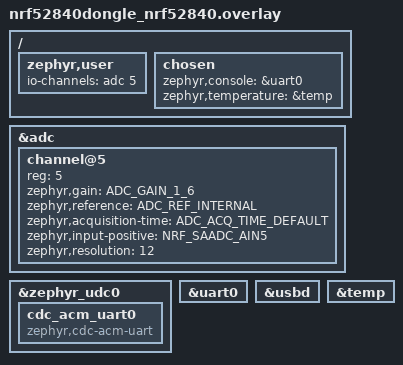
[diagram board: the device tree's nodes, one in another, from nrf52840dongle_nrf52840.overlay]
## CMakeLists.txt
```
# SPDX-License-Identifier: Apache-2.0

cmake_minimum_required(VERSION 3.20.0)
find_package(Zephyr REQUIRED HINTS $ENV{ZEPHYR_BASE})
project(central)

target_sources(app PRIVATE
  src/main.c
  src/util.c
  src/cmd_handler.c
  src/md_cmd.c
  src/shell.c
)

zephyr_library_include_directories(${ZEPHYR_BASE}/samples/bluetooth)
```

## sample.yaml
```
sample:
  name: Bluetooth Central
tests:
  sample.bluetooth.central:
    harness: bluetooth
    platform_allow: qemu_cortex_m3 qemu_x86
    tags: bluetooth
    integration_platforms:
      - qemu_cortex_m3
```

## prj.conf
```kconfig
CONFIG_BT=y
CONFIG_BT_CENTRAL=y
CONFIG_BT_EXT_ADV=y
CONFIG_BT_PER_ADV_SYNC=y
CONFIG_BT_DEBUG_LOG=y
CONFIG_BT_DEVICE_NAME="Central Periodic Advertising Receiver"
CONFIG_BT_PER_ADV_SYNC_TRANSFER_SENDER=y
CONFIG_BT_GATT_CLIENT=y

# enable uart driver
CONFIG_SERIAL=y
CONFIG_UART_INTERRUPT_DRIVEN=y
CONFIG_UART_LINE_CTRL=y

# enable console
CONFIG_CONSOLE=y
CONFIG_UART_CONSOLE=y
CONFIG_STDOUT_CONSOLE=y

CONFIG_USB_DEVICE_INITIALIZE_AT_BOOT=n
CONFIG_USB_DEVICE_STACK=y
CONFIG_USB_DEVICE_PRODUCT="BLE Throttle Central"

CONFIG_BT_DIS=y
CONFIG_BT_DIS_SERIAL_NUMBER=y
CONFIG_BT_DIS_MODEL="nRF52840_Acserver"
CONFIG_BT_DIS_MANUF="Br1Ge9se"
CONFIG_BT_DIS_SERIAL_NUMBER_STR="001001"

CONFIG_GETOPT=y
CONFIG_GETOPT_LONG=y

CONFIG_DK_LIBRARY=y
CONFIG_SENSOR=y
CONFIG_CBPRINTF_FP_SUPPORT=y

# Temperature sensor
CONFIG_TEMP_NRF5=y

# enable console for nRF52840 DK 
#CONFIG_CONSOLE_SUBSYS=y
#CONFIG_CONSOLE_GETCHAR=y
#CONFIG_CONSOLE_GETCHAR_BUFSIZE=64
#CONFIG_CONSOLE_PUTCHAR_BUFSIZE=512
```

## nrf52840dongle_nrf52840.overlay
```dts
/*
 * Copyright (c) 2021 Nordic Semiconductor ASA
 *
 * SPDX-License-Identifier: Apache-2.0
 */

 &adc {
	#address-cells = <1>;
	#size-cells = <0>;

	channel@5 {
		reg = <5>;
		zephyr,gain = "ADC_GAIN_1_6";
		zephyr,reference = "ADC_REF_INTERNAL";
		zephyr,acquisition-time = <ADC_ACQ_TIME_DEFAULT>;
		zephyr,input-positive = <NRF_SAADC_AIN5>; /* P0.03 */
		zephyr,resolution = <12>;
	};

};

&zephyr_udc0 {
	cdc_acm_uart0 {
		compatible = "zephyr,cdc-acm-uart";
	};
};

&uart0 {
    status = "okay";
};

&usbd {
    status = "okay";
};

/ {
    zephyr,user {
		io-channels = <&adc 5>;
	};
    
	chosen {
		/* zephyr,console = &usbd; */
		zephyr,console = &uart0;
		zephyr,temperature = &temp;
	};
};

&temp {
	status = "okay";
};
```

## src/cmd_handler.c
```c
/**
 * @file
 * @brief Shell Commands Handler
 *
 */

#include <string.h>
#include <stdio.h>
#include "util.h"

#define MAX_CMD 6

#define COMMAND_SUCCESS		0
#define COMMAND_ERROR		1
#define COMMAND_ERROR_USAGE	2

/*
 * Monitor Command Table
 */
typedef struct command {
	const char	*name;		/* Command Name			*/
	int		(*cmd)(int, char *[]); /* Implementation function	*/
	const char	*desc;		/* Short command description, start with lowercase */
	const char	*help;
}command;

extern int mem_md(int argc, char *argv[]);
extern int ble_info(void);
extern int print_rx_value(void);
extern int print_temp_value(void);

int helpCmd(int argc, char *argv[]);
int versCmd(int argc, char *argv[]);

struct command cmdTable[MAX_CMD] = {
		{"version", versCmd, "print out version info", NULL},
		{"info", ble_info, "print out BLE info", NULL},
		{"help", helpCmd, "print out command list", NULL},
		{"val", print_rx_value, "print out BLE Rx Value from client", NULL},
		{"temp", print_temp_value, "print out chip temperature", NULL},
		{"md", mem_md, "display (hex dump) a memory region",
		"Memory regions can be specified in two different forms: START+SIZE or START-END, if SIZE is omitted it defaults to 0x100"}
};


#define VERSION "  Shell V0.1 (beta) - "

int versCmd(int argc, char *argv[])
{
	char s1[60]=VERSION, s2[]=__DATE__, s3[]=__TIME__;
	strcat(s1, s2);
	strcat(s1, " * ");
	strcat(s1, s3);
	nc_printf ("\n%s\n\n", s1);
	return (COMMAND_SUCCESS);
}

char * help_string = "  ****** Commands help ******";

int helpCmd(int argc, char *argv[])
{
	int i;
	nc_printf ("\n\r%s\n\r", help_string);
	for (i=0; i<MAX_CMD; i++)
	{
		nc_printf("%s - %s\n\r", cmdTable[i].name, cmdTable[i].desc);
	}
	console_putc('\n');
	return (COMMAND_SUCCESS);
}


void cmd_usage(struct command *cmdtp)
{
	if (cmdtp->desc)
		nc_printf("\n%s - %s\n\n", cmdtp->name, cmdtp->desc);
	if (cmdtp->help)
		nc_printf("\nUsage: %s %s\n\n", cmdtp->name, cmdtp->help);
}

/*
 * find command table entry for a command
 */
struct command *find_cmd (const char *cmd)
{
	struct command *cmdtp;
	int i;

	for (i=0; i<MAX_CMD; i++) {
		cmdtp = &cmdTable[i];
		if (!strcmp(cmd, cmdtp->name))
			return cmdtp;
	}
	return NULL;	/* not found or ambiguous command */
}

int execute_command(int argc, char **argv)
{
	struct command *cmdtp;
	int ret;

	/* Look up command in command table */
	if ((cmdtp = find_cmd(argv[0]))) {
		/* OK - call function to do the command */
		ret = cmdtp->cmd(argc, argv);
		if (ret == COMMAND_ERROR_USAGE) {
			cmd_usage(cmdtp);
			ret = COMMAND_ERROR;
		}
	} else {
		nc_printf ("Unknown command '%s'\n", argv[0]);
		ret = COMMAND_ERROR;	/* give up after bad command */
	}
	return ret;
}
```

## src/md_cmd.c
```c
/**
 * Memory Functions
 *
 * Copied from FADS ROM, Dan Malek (dmalek@jlc.net)
 */



#include "util.h"

#define MSG_EMERG      0    /* system is unusable */
#define O_RWSIZE_SHIFT	18
#define O_RWSIZE_1	001000000
#define O_RWSIZE_2	002000000
#define O_RWSIZE_4	004000000
#define O_RWSIZE_8	010000000

#define PROT_READ	1

#define RW_BUF_SIZE	(unsigned)4096

#define COMMAND_SUCCESS		0
#define COMMAND_ERROR		1
#define COMMAND_ERROR_USAGE	2

#ifdef VERBOSE_DEBUG
#define LOGLEVEL	3
#elif defined DEBUG
#define LOGLEVEL	2
#else
#define LOGLEVEL	1
#endif

#define MAP_FAILED ((void *)-1)

#define DISP_LINE_LEN	16

typedef long long loff_t;
struct va_format {
	const char *fmt;
	va_list *va;
};

extern int optind;

volatile int arm_ignore_data_abort;
volatile int arm_data_abort_occurred;


/**
 * swab64 - return a byteswapped 64-bit value
 * @x: value to byteswap
 */
unsigned long long int swab64 (unsigned long long int x) {
    unsigned long long int ret = 0;
    unsigned char c;
    unsigned char * p = (unsigned char *) &x;
	int i;
    
    for (i=0; i<7; i++) {
        c = p[i];
        ret += c;
        ret = ret << 8;
    }
	c = p[i];
    ret += c;
    return ret;
}

/**
 * swab32 - return a byteswapped 32-bit value
 * @x: value to byteswap
 */
unsigned int swab32 (unsigned int x) {
    unsigned int i, ret = 0;
    unsigned char c;
    unsigned char * p = (unsigned char *) &x;
    
    for (i=0; i<3; i++) {
        c = p[i];
        ret += c;
        ret = ret << 8;
    }
	c = p[i];
    ret += c;
    return ret;
}

/**
 * swab16 - return a byteswapped 16-bit value
 * @x: value to byteswap
 */
unsigned short int swab16 (unsigned short int x) {
    unsigned short int ret = 0;
    unsigned char * p = (unsigned char *) &x;
    
	ret += p[0];
	ret = ret << 8;
	ret += p[1];

    return ret;
}


void data_abort_mask(void)
{
	arm_data_abort_occurred = 0;
	arm_ignore_data_abort = 1;
}

int data_abort_unmask(void)
{
	arm_ignore_data_abort = 0;

	return arm_data_abort_occurred != 0;
}

int memory_display(const void *addr, loff_t offs, unsigned nbytes, int size,
		   int swab);
int __pr_memory_display(int level, const void *addr, loff_t offs, unsigned nbytes,
			int size, int swab, const char *format, ...);

#define pr_fmt(fmt) fmt
#define pr_memory_display(level, addr, offs, nbytes, size, swab) \
	({	\
		(level) <= LOGLEVEL ? __pr_memory_display((level), (addr), \
				(offs), (nbytes), (size), (swab), pr_fmt("")) : 0; \
	 })

int __pr_memory_display(int level, const void *addr, loff_t offs, unsigned nbytes,
			int size, int swab, const char *fmt, ...)
{	        
	unsigned long linebytes, i;
	unsigned char *cp;
	unsigned char line[sizeof("00000000: 0000 0000 0000 0000  0000 0000 0000 0000            ................")];
	struct va_format vaf;
	int ret;
	va_list args;

	va_start(args, fmt);

	vaf.fmt = fmt;
	vaf.va = &args;

	/* Print the lines.
	 *
	 * We buffer all read data, so we can make sure data is read only
	 * once, and all accesses are with the specified bus width.
	 */
	do {
		unsigned char linebuf[DISP_LINE_LEN];
		uint64_t *ullp = (uint64_t *)linebuf;
		uint32_t *uip = (uint32_t *)linebuf;
		uint16_t *usp = (uint16_t *)linebuf;
		uint8_t *ucp = (uint8_t *)linebuf;
		unsigned char *pos = line;

		pos += sprintf(pos, "%08llx:", offs);
		linebytes = (nbytes > DISP_LINE_LEN) ? DISP_LINE_LEN : nbytes;

		for (i = 0; i < linebytes; i += size) {
			if (size == 8) {
				uint64_t res;
				data_abort_mask();
				res = *((uint64_t *)addr);
				if (swab)
					res = swab64(res);
				if (data_abort_unmask()) {
					res = 0xffffffffffffffffULL;
					pos += sprintf(pos, " xxxxxxxxxxxxxxxx");
				} else {
					pos += sprintf(pos, " %016llx", res);
				}
				*ullp++ = res;
			} else if (size == 4) {
				uint32_t res;
				data_abort_mask();
				res = *((uint32_t *)addr);
				if (swab)
					res = swab32(res);
				if (data_abort_unmask()) {
					res = 0xffffffff;
					pos += sprintf(pos, " xxxxxxxx");
				} else {
					pos += sprintf(pos, " %08x", res);
				}
				*uip++ = res;
			} else if (size == 2) {
				uint16_t res;
				data_abort_mask();
				res = *((uint16_t *)addr);
				if (swab)
					res = swab16(res);
				if (i > 1 && i % 8 == 0)
					pos += sprintf(pos, " ");
				if (data_abort_unmask()) {
					res = 0xffff;
					pos += sprintf(pos, " xxxx");
				} else {
					pos += sprintf(pos, " %04x", res);
				}
				*usp++ = res;
			} else {
				uint8_t res;
				data_abort_mask();
				res = *((uint8_t *)addr);
				if (i > 1 && i % 8 == 0)
					pos += sprintf(pos, " ");
				if (data_abort_unmask()) {
					res = 0xff;
					pos += sprintf(pos, " xx");
				} else {
					pos += sprintf(pos, " %02x", res);
				}
				*ucp++ = res;
			}
			addr += size;
			offs += size;
		}

		pos += sprintf(pos, "%*s", (int)(61 - (pos - line)), "");

		cp = linebuf;
		for (i = 0; i < linebytes; i++) {
			if ((*cp < 0x20) || (*cp > 0x7e))
				sprintf(pos, ".");
			else
				sprintf(pos, "%c", *cp);
			pos++;
			cp++;
		}

//		if (level >= MSG_EMERG)
//			xil_printf(level, "%pV%s\n", &vaf, line);
//		else
			nc_printf("%s\n", line);
//			k_sleep(K_MSEC(20));

		nbytes -= linebytes;
		if (ctrlc()) {
			ret = -EINTR;
			goto out;
		}

	} while (nbytes > 0);

	va_end(args);
	ret = 0;
out:

	return ret;
}

int memory_display(const void *addr, loff_t offs, unsigned nbytes,
		   int size, int swab)
{
	return pr_memory_display(-1, addr, offs, nbytes, size, swab);
}

/*
 * Common function for parsing options for the 'md', 'mw', 'memcpy', 'memcmp'
 * commands.
 */
int mem_parse_options(int argc, char *argv[], char *optstr, int *mode, int *swab)
{
	int opt;

	while((opt = getopt(argc, argv, optstr)) > 0) {
		switch(opt) {
		case 'b':
			*mode = O_RWSIZE_1;
			break;
		case 'w':
			*mode = O_RWSIZE_2;
			break;
		case 'l':
			*mode = O_RWSIZE_4;
			break;
		case 'q':
			*mode = O_RWSIZE_8;
			break;
		case 'x':
			*swab = 1;
			break;
		default:
			return -EINVAL;
		}
	}

	return 0;
}

/*
 * Like simple_strtoull() but handles an optional G, M, K or k
 * suffix for Gigabyte, Megabyte or Kilobyte
 */
unsigned long long strtoull_suffix(const char *str, char **endp, int base)
{
	unsigned long long val;
	char *end;

	val = strtoull(str, &end, base);

	switch (*end) {
	case 'G':
		val *= 1024;
	case 'M':
		val *= 1024;
	case 'k':
	case 'K':
		val *= 1024;
		end++;
	default:
		break;
	}

	if (strncmp(end, "iB", 2) == 0)
		end += 2;

	if (endp)
		*endp = end;

	return val;
}


unsigned long strtoul_suffix(const char *str, char **endp, int base)
{
	return strtoull_suffix(str, endp, base);
}


/*
 * This function parses strings in the form <startadr>[-endaddr]
 * or <startadr>[+size] and fills in start and size accordingly.
 * <startadr> and <endadr> can be given in decimal or hex (with 0x prefix)
 * and can have an optional G, M, K or k suffix.
 *
 * examples:
 * 0x1000-0x2000 -> start = 0x1000, size = 0x1001
 * 0x1000+0x1000 -> start = 0x1000, size = 0x1000
 * 0x1000        -> start = 0x1000, size = ~0
 * 1M+1k         -> start = 0x100000, size = 0x400
 */
int parse_area_spec(const char *str, loff_t *start, loff_t *size)
{
	char *endp;
	loff_t end, _start, _size;

	if (!isdigit(*str))
		return -1;

	_start = strtoull_suffix(str, &endp, 0);

	str = endp;

	if (!*str) {
		/* beginning given, but no size, assume maximum size */
		_size = ~0;
		goto success;
	}

	if (*str == '-') {
		/* beginning and end given */
		if (!isdigit(*(str + 1)))
			return -1;

		end = strtoull_suffix(str + 1, &endp, 0);
		str = endp;
		if (end < _start) {
			nc_printf("end < start\n");
			return -1;
		}
		_size = end - _start + 1;
		goto success;
	}

	if (*str == '+') {
		/* beginning and size given */
		if (!isdigit(*(str + 1)))
			return -1;

		_size = strtoull_suffix(str + 1, &endp, 0);
		str = endp;
		goto success;
	}

	return -1;

success:
	if (*str && !isspace(*str))
		return -1;
	*start = _start;
	*size = _size;
	return 0;
}

int mem_md(int argc, char *argv[])
{
	loff_t	start = 0, size = 0x100;
	int	ret = 0;
	int mode = O_RWSIZE_4;
	int swab = 0;
	void *map = NULL;

	if (argc < 2)
		return COMMAND_ERROR_USAGE;

	if (mem_parse_options(argc, argv, "bwlqs:x", &mode,	&swab) < 0)
		return 1;

	if (optind < argc) {
		if (parse_area_spec(argv[optind], &start, &size)) {
			nc_printf("could not parse: %s\n", argv[optind]);
			return 1;
		}
		if (size == ~0)
			size = 0x100;
	}
	/*
	if (((start>0x20040000) || (start<0x20000000) ) || ((size)>0x00040000))
	{
		nc_printf("Invalid memory (valid ram: 0x20000000-0x20040000)\n");
		return 1;
	}
	*/
	ret = memory_display(map + start, start, size, mode >> O_RWSIZE_SHIFT, swab);

	optind = 1;

	return ret ? 1 : 0;
}
```

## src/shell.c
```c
/**
 * @file
 * @brief Simple Shell/Command Parser
 *
 */
#include <zephyr/types.h>
#include <stddef.h>
#include <errno.h>
#include <stdlib.h>
#include <zephyr/kernel.h>
#include "shell.h"
#include "util.h"

#define CONFIG_CBSIZE 128
#define CONFIG_MAXARGS 5
#define CONFIG_PROMPT "shell>"
#ifndef __maybe_unused
#define __maybe_unused		__attribute__((unused))
#endif

static char console_buffer[CONFIG_CBSIZE];		/* console I/O buffer	*/
static char erase_seq[] = "\b \b";		/* erase sequence	*/
static char   tab_seq[] = "        ";		/* used to expand TABs	*/

#define COMMAND_SUCCESS		0
int execute_command(int argc, char **argv);

extern char* itoa(int num, char* str, int base);
extern int nc_getchar(void);


static char * delete_char (char *buffer, char *p, int *colp, int *np, int plen)
{
	char *s;

	if (*np == 0) {
		return (p);
	}

	if (*(--p) == '\t') {			/* will retype the whole line	*/
		while (*colp > plen) {
			nc_puts (erase_seq);
			(*colp)--;
		}
		for (s=buffer; s<p; ++s) {
			if (*s == '\t') {
				nc_puts (tab_seq+((*colp) & 07));
				*colp += 8 - ((*colp) & 07);
			} else {
				++(*colp);
				console_putc (*s);
			}
		}
	} else {
		nc_puts (erase_seq);
		(*colp)--;
	}
	(*np)--;
	return (p);
}

/*
 * Prompt for input and read a line.
 * Return:	number of read characters
 *		-1 if break
 */
int readline (const char *prompt, char *line, int len)
{
	static char *p;
	static int	n = 0;				/* buffer index		*/
	static int	plen = 0;			/* prompt length	*/
	static int fprompt = 0;			/* flag */
	int	col;						/* output column cnt	*/
	int	c;

	if (!fprompt) {
		/* print prompt */
		if (prompt) {
			plen = strlen (prompt);
			nc_puts (prompt);
			memset(line, 0, len);
			fprompt = 1;
			p = line;
			n = 0;
		}
	}
	col = plen;

	c = nc_getchar();
	if (c < 0)
		return (-1);

	/*
	 * Special character handling
	 */
	switch (c) {
		case '\r':				/* Enter		*/
		case '\n':
			*p = '\0';
			nc_puts ("\r\n");
			fprompt = 0;
			return (p - line);

		case '\0':				/* nul			*/
			break;

		case 0x03:				/* ^C - break		*/
			line[0] = '\0';	/* discard input */
			fprompt = 0;
			nc_puts ("\r\n");
			return (-1);

		case 0x15:				/* ^U - erase line	*/
			while (col > plen) {
				nc_puts (erase_seq);
				--col;
			}
			p = line;
			n = 0;
			break;

		case 0x17:				/* ^W - erase word 	*/
			p=delete_char(line, p, &col, &n, plen);
			while ((n > 0) && (*p != ' ')) {
				p=delete_char(line, p, &col, &n, plen);
			}
			break;

		case 0x08:				/* ^H  - backspace	*/
		case 0x7F:				/* DEL - backspace	*/
			p=delete_char(line, p, &col, &n, plen);
			break;

		default:
			/*
			 * Must be a normal character then
			 */
			if (n < len-2) {
				if (c == '\t') {	/* expand TABs		*/
					nc_puts (tab_seq+(col&07));
					col += 8 - (col&07);
				} else {
					++col;		/* echo input		*/
					console_putc (c);
				}
				*p++ = c;
				++n;
			} else {			/* Buffer full		*/
				console_putc ('\a');
			}
			break;
	}
	return 0;
}

static int parse_line (char *line, char *argv[])
{
	int nargs = 0;

//	xil_printf("parse_line: %s\r\n", line);

	while (nargs < CONFIG_MAXARGS) {

		/* skip any white space */
		while ((*line == ' ') || (*line == '\t')) {
			++line;
		}

		if (*line == '\0') {	/* end of line, no more args	*/
			argv[nargs] = NULL;

//			xil_printf("parse_line: nargs=%d\n\r", nargs);

			return (nargs);
		}

		argv[nargs++] = line;	/* begin of argument string	*/

		/* find end of string */
		while (*line && (*line != ' ') && (*line != '\t')) {
			++line;
		}

		if (*line == '\0') {	/* end of line, no more args	*/
			argv[nargs] = NULL;

//			xil_printf("parse_line: nargs=%d\n\r", nargs);

			return (nargs);
		}

		*line++ = '\0';		/* terminate current arg	 */
	}

//	xil_printf ("** Too many args (max. %d) **\n\r", CONFIG_MAXARGS);
	nc_puts("** Too many args (max. ");
	char bf[2] = {0,0};
	itoa(CONFIG_MAXARGS, bf, 10);
	nc_puts(bf);
	nc_puts(") **\n\r");
//	xil_printf("parse_line: nargs=%d\n\r", nargs);
	return (nargs);
}

static void process_macros (const char *input, char *output)
{
	char c, prev;
	const char *varname_start = NULL;
	int inputcnt = strlen (input);
	int outputcnt = CONFIG_CBSIZE;
	int state = 0;		/* 0 = waiting for '$'  */

	/* 1 = waiting for '(' or '{' */
	/* 2 = waiting for ')' or '}' */
	/* 3 = waiting for '''  */
	char __maybe_unused *output_start = output;

//	xil_printf("[PROCESS_MACROS] INPUT len %d: - %s\r\n", strlen (input), input);

	prev = '\0';		/* previous character   */

	while (inputcnt && outputcnt) {
		c = *input++;
		inputcnt--;

		if (state != 3) {
			/* remove one level of escape characters */
			if ((c == '\\') && (prev != '\\')) {
				if (inputcnt-- == 0)
					break;
				prev = c;
				c = *input++;
			}
		}

		switch (state) {
		case 0:	/* Waiting for (unescaped) $    */
			if ((c == '\'') && (prev != '\\')) {
				state = 3;
				break;
			}
			if ((c == '$') && (prev != '\\')) {
				state++;
			} else {
				*(output++) = c;
				outputcnt--;
			}
			break;
		case 1:	/* Waiting for (        */
			if (c == '(' || c == '{') {
				state++;
				varname_start = input;
			} else {
				state = 0;
				*(output++) = '$';
				outputcnt--;

				if (outputcnt) {
					*(output++) = c;
					outputcnt--;
				}
			}
			break;
		case 2:	/* Waiting for )        */
			if (c == ')' || c == '}') {
				int i;
				char envname[CONFIG_CBSIZE];
				const char *envval;
				int envcnt = input - varname_start - 1;	/* Varname # of chars */

				/* Get the varname */
				for (i = 0; i < envcnt; i++) {
					envname[i] = varname_start[i];
				}
				envname[i] = 0;

				/* Get its value */
				envval = getenv (envname);

				/* Copy into the line if it exists */
				if (envval != NULL)
					while ((*envval) && outputcnt) {
						*(output++) = *(envval++);
						outputcnt--;
					}
				/* Look for another '$' */
				state = 0;
			}
			break;
		case 3:	/* Waiting for '        */
			if ((c == '\'') && (prev != '\\')) {
				state = 0;
			} else {
				*(output++) = c;
				outputcnt--;
			}
			break;
		}
		prev = c;
	}

	if (outputcnt)
		*output = 0;
/*
	xil_printf("[PROCESS_MACROS] INPUT len %d: - %s\r\n",
		strlen (output_start), output_start);
*/
}

/**
 * @brief Run command.
 *
 * @param cmd - command name string
 *
 * @return int - 0: command executed,
 *               -1: not executed
 *                -unrecognized or too many args
 *                -If cmd is NULL or "" or longer than
 *               CONFIG_CBSIZE-1 it is considered unrecognized
 */

int run_command(const char *cmd)
{
	char cmdbuf[CONFIG_CBSIZE];	/* working copy of cmd		*/
	char *token;			/* start of token in cmdbuf	*/
	char *sep;			/* end of token (separator) in cmdbuf */
	char finaltoken[CONFIG_CBSIZE];
	char *str = cmdbuf;
	char *argv[CONFIG_MAXARGS + 1];	/* NULL terminated	*/
	int argc, inquotes;
	int rc = 0;

#ifdef DEBUG
	xil_printf("[RUN_COMMAND] cmd[%p]=", cmd);
	xil_printf (cmd ? cmd : "NULL");	/* use puts - string may be loooong */
	xil_printf ("\r\n");
#endif

	if (!cmd || !*cmd) {
		return -1;	/* empty command */
	}

	if (strlen(cmd) >= CONFIG_CBSIZE) {
		nc_puts ("## Command too long!\n\r");
		return -1;
	}

	strcpy (cmdbuf, cmd);

	/*
	 * Process separators and check for invalid
	 * repeatable commands
	 */

//	xil_printf("[PROCESS_SEPARATORS] %s\n\r", cmd);

	while (*str) {

		/*
		 * Find separator, or string end
		 * Allow simple escape of ';' by writing "\;"
		 */
		for (inquotes = 0, sep = str; *sep; sep++) {
			if ((*sep=='\'') &&
			    (*(sep-1) != '\\'))
				inquotes=!inquotes;

			if (!inquotes &&
			    (*sep == ';') &&	/* separator		*/
			    ( sep != str) &&	/* past string start	*/
			    (*(sep-1) != '\\'))	/* and NOT escaped	*/
				break;
		}

		/*
		 * Limit the token to data between separators
		 */
		token = str;
		if (*sep) {
			str = sep + 1;	/* start of command for next pass */
			*sep = '\0';
		}
		else {
			str = sep;	/* no more commands for next pass */
		}

	//	xil_printf("token: %s\r\n", token);

		/* find macros in this token and replace them */
		process_macros (token, finaltoken);

		/* Extract arguments */
		if ((argc = parse_line (finaltoken, argv)) == 0) {
			rc = -1;	/* no command at all */
			continue;
		}

		if (execute_command(argc, argv) != COMMAND_SUCCESS)
			rc = -1;
	}

	return rc;
}

/**
 * @brief The shell entry point.
 *
 * This is called as part of machine loop.
 *
 * @return void
 */
void run_shell (void)
{
    static char lastcommand[CONFIG_CBSIZE] = { 0, };
	int len;

	if (console_active()) {
		len = readline (CONFIG_PROMPT, console_buffer, CONFIG_CBSIZE);
		if (len > 0) {
			strcpy (lastcommand, console_buffer);
			const int rc = run_command(lastcommand);
			if (rc < 0) {
				/* invalid command or not repeatable, forget it */
				lastcommand[0] = 0;
			}
			ctrlc_handled();
		}
	}
}
```

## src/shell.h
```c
 #ifndef NC_PRINTF_H
 #define NC_PRINTF_H

#include <zephyr/types.h>
#include <stddef.h>
#include <errno.h>
#include <zephyr/kernel.h>

#include <ctype.h>
#include <string.h>
#include <stdarg.h>
#include "types.h"

/*----------------------------------------------------*/
/* Use the following parameter passing structure to   */
/* make nc_printf re-entrant.                        */
/*----------------------------------------------------*/

struct params_s;

/*               Prototypes                          */

void nc_printf( const char8 *ctrl1, ...);
void nc_print( const char8 *ptr);
int nc_puts(const char *str);
//extern void nc_putc (unsigned char c);
extern void console_putc (unsigned char c);
#define nc_putc console_putc


#endif	/* end of protection macro */
```

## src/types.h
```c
#ifndef TYPES_H
#define TYPES_H

#include <stdint.h>
#include <stddef.h>

/************************** Constant Definitions *****************************/

#ifndef TRUE
#  define TRUE		1U
#endif

#ifndef FALSE
#  define FALSE		0U
#endif

#ifndef NULL
#define NULL		0U
#endif

#define XIL_COMPONENT_IS_READY     0x11111111U  /**< In device drivers, This macro will be
                                                 assigend to "IsReady" member of driver
												 instance to indicate that driver
												 instance is initialized and ready to use. */
#define XIL_COMPONENT_IS_STARTED   0x22222222U  /**< In device drivers, This macro will be assigend to
                                                 "IsStarted" member of driver instance
												 to indicate that driver instance is
												 started and it can be enabled. */

/* @name New types
 * New simple types.
 * @{
 */
#ifndef __KERNEL__
#ifndef XBASIC_TYPES_H
/*
 * guarded against xbasic_types.h.
 */
typedef uint8_t u8;
typedef uint16_t u16;
typedef uint32_t u32;
/** @}*/
#define __XUINT64__
typedef struct
{
	u32 Upper;
	u32 Lower;
} Xuint64;

typedef char * charptr;
//typedef s32 (*func_ptr)(int c);

/*****************************************************************************/
/**
* @brief    Return the most significant half of the 64 bit data type.
*
* @param    x is the 64 bit word.
*
* @return   The upper 32 bits of the 64 bit word.
*
******************************************************************************/
#define XUINT64_MSW(x) ((x).Upper)

/*****************************************************************************/
/**
* @brief    Return the least significant half of the 64 bit data type.
*
* @param    x is the 64 bit word.
*
* @return   The lower 32 bits of the 64 bit word.
*
******************************************************************************/
#define XUINT64_LSW(x) ((x).Lower)

#endif /* XBASIC_TYPES_H */

/*
 * xbasic_types.h does not typedef s* or u64
 */
/** @{ */
typedef char char8;
typedef int8_t s8;
typedef int16_t s16;
typedef int32_t s32;
typedef int64_t s64;
typedef uint64_t u64;
typedef int sint32;
typedef uint16_t u16_t;
typedef uint8_t u8_t;
typedef int16_t s16_t;

#if defined(__MICROBLAZE__) && !defined(__arch64__) && \
    (XPAR_MICROBLAZE_ADDR_SIZE > 32)
typedef uint64_t UINTPTR;
typedef int64_t INTPTR;
#else
typedef uintptr_t UINTPTR;
typedef intptr_t INTPTR;
#endif

typedef ptrdiff_t PTRDIFF;
/** @}*/
#if !defined(LONG) || !defined(ULONG)
typedef long LONG;
typedef unsigned long ULONG;
#endif

#define ULONG64_HI_MASK	0xFFFFFFFF00000000U
#define ULONG64_LO_MASK	~ULONG64_HI_MASK

#else
#include <linux/types.h>
#endif

/** @{ */
/**
 * This data type defines an interrupt handler for a device.
 * The argument points to the instance of the component
 */
typedef void (*XInterruptHandler) (void *InstancePtr);

/**
 * This data type defines an exception handler for a processor.
 * The argument points to the instance of the component
 */
typedef void (*XExceptionHandler) (void *InstancePtr);

#if defined (__riscv_xlen) && (__riscv_xlen == 64)
#define __arch64__
#endif

/**
 * @brief  Returns 32-63 bits of a number.
 * @param  n : Number being accessed.
 * @return Bits 32-63 of number.
 *
 * @note    A basic shift-right of a 64- or 32-bit quantity.
 *          Use this to suppress the "right shift count >= width of type"
 *          warning when that quantity is 32-bits.
 */
#if defined (__aarch64__) || defined (__arch64__)
#define UPPER_32_BITS(n) ((u32)(((n) >> 16) >> 16))
#else
#define UPPER_32_BITS(n) 0U
#endif
/**
 * @brief  Returns 0-31 bits of a number
 * @param  n : Number being accessed.
 * @return Bits 0-31 of number
 */
#define LOWER_32_BITS(n) ((u32)(n))

/**
 * @brief   Returns 0-31 bits of a number .
 * @param   n : Number being accessed.
 * @return  Bits 0-31 of number.
 */
#if defined (__aarch64__) || defined (__arch64__)
#define LEFT_SHIFT_BY_32_BITS(n) (u64)(((u64)n) << 32)
#else
#define LEFT_SHIFT_BY_32_BITS(n) 0U
#endif

/************************** Constant Definitions *****************************/

#ifndef TRUE
#define TRUE		1U
#endif

#ifndef FALSE
#define FALSE		0U
#endif

#ifndef NULL
#define NULL		0U
#endif


#endif	/* end of protection macro */
```

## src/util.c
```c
/*
 * Copyright (c) 2025 Br1Ge9se
 * All rights reserved. 
 * 
 * Redistribution and use in source and binary forms, with or without modification, 
 * are permitted provided that the following conditions are met:
 *
 * 1. Redistributions of source code must retain the above copyright notice,
 *    this list of conditions and the following disclaimer.
 * 2. Redistributions in binary form must reproduce the above copyright notice,
 *    this list of conditions and the following disclaimer in the documentation
 *    and/or other materials provided with the distribution.
 * 3. The name of the author may not be used to endorse or promote products
 *    derived from this software without specific prior written permission. 
 *
 * THIS SOFTWARE IS PROVIDED BY THE AUTHOR ``AS IS'' AND ANY EXPRESS OR IMPLIED 
 * WARRANTIES, INCLUDING, BUT NOT LIMITED TO, THE IMPLIED WARRANTIES OF 
 * MERCHANTABILITY AND FITNESS FOR A PARTICULAR PURPOSE ARE DISCLAIMED. IN NO EVENT 
 * SHALL THE AUTHOR BE LIABLE FOR ANY DIRECT, INDIRECT, INCIDENTAL, SPECIAL, 
 * EXEMPLARY, OR CONSEQUENTIAL DAMAGES (INCLUDING, BUT NOT LIMITED TO, PROCUREMENT 
 * OF SUBSTITUTE GOODS OR SERVICES; LOSS OF USE, DATA, OR PROFITS; OR BUSINESS 
 * INTERRUPTION) HOWEVER CAUSED AND ON ANY THEORY OF LIABILITY, WHETHER IN 
 * CONTRACT, STRICT LIABILITY, OR TORT (INCLUDING NEGLIGENCE OR OTHERWISE) ARISING 
 * IN ANY WAY OUT OF THE USE OF THIS SOFTWARE, EVEN IF ADVISED OF THE POSSIBILITY 
 * OF SUCH DAMAGE.
 *
 * 
 * Author: Bruno Genovese <br1ge9se>
 *
 */

/**
 * @file
 * @brief Utilities functions
 *
 */
 
#include "util.h"

static ENV env[ENVNUM];

static const struct device *dev = NULL;

static bool print_flag = false;

static int ctrlc_abort;

extern int nc_getchar(void);


/**
 * @brief 
 *
 * 
 */
void set_print_flag(bool val) {
    print_flag = val;
}

/**
 * @brief 
 *
 * 
 */
bool chk_print_flag(void) {
#ifdef DONGLE
    return (print_flag);
#else
    return true;
#endif
}
/**
 * @brief 
 *
 * 
 */
void initenv(void) {
    
}

/**
 * @brief 
 *
 * 
 */
void clrenv(void) {
	for (int i=0; i<ENVNUM; i++) {
		for (int j=0; j<VARSIZE; j++) {
			env[i].name[j] = 0;
			env[i].value[j] = 0;
		}

	}
}

/**
 * @brief Set enviromental variable
 * @param env. var. name
 * @param env. var. value
 *
 * @return success or error value 
 */
int setenv(const char * env_name, const char * env_value) {
	int nlen = strlen(env_name);
	int vlen = strlen(env_value);
	int i, ret = 0;
    
	if ((env_name != NULL) && (nlen != 0)) {
		if (nlen > VARSIZE)
			nlen = VARSIZE;
		if (vlen > VARSIZE)
			vlen = VARSIZE;
        // search for env name
		for (i=0; i<ENVNUM; i++) {
			if (strncmp(env_name, env[i].name, nlen) == 0) {
				strncpy(env[i].value, env_value, vlen);
				break;
			}
		}
		if (i == ENVNUM) {
           // name not found, create it
			for (i=0; i<ENVNUM; i++) {
				if (env[i].name[0] == 0) {
                    // free, place here
					strncpy(env[i].name, env_name, nlen);
					strncpy(env[i].value, env_value, vlen);
				}
			}
            if (i == ENVNUM) {
                // no free space
                ret = ERR_ENVFULL;
            }
		}
    } else {
        // wrong parameters
        ret = ERR_ENVPARAM;
    }
    return (ret);
}

/**
 * @brief Get enviromental variable
 * @param env. var. name
 *
 * @return value string pointer or NULL on error
 */
const char * getenv(const char *env_name) {
    int j, nlen;
    if (env_name != NULL) {
        nlen = strlen(env_name);
        if (nlen > VARSIZE)
            nlen = VARSIZE;
        for(j=0; j<nlen; j++){
            if (strncmp(env_name, env[j].name, nlen) == 0) {
                return (env[j].value);
            }
        }
	}
    return NULL;
}

/**
 * @brief 
 *
 * 
 */
void init_console(const struct device *mydev)
{
    dev = mydev;
}

/**
 * @brief Default character output routine
 * @param c Character to swallow
 *
 */
void console_putc(unsigned char c)
{
    if ((dev != NULL) && (chk_print_flag() == true)) {
        uart_poll_out(dev, c);
        if (c == '\n')
			uart_poll_out(dev, '\r');
    }
}

/**
 * @brief Default string output routine
 * @param pointer to the string
 *
 */
static int console_puts(const char *str)
{
	int n = 0;

	while (*str) {
//		if (*str == '\n')
//			console_putc('\r');

		console_putc(*str);
		str++;
		n++;
	}

	return n;
}

/**
 * @brief Default printf routine
 * @param args
 *
 */
int zprintf(const char *fmt, ...)
{
	va_list args;
	unsigned int i;
	char printbuffer[CFG_PBSIZE];

	va_start(args, fmt);
	i = vsprintf(printbuffer, fmt, args);
	va_end(args);
#ifdef DONGLE
	console_puts(printbuffer);
#else
    printk("%s", printbuffer);
#endif

	return i;
}

/**
 * @brief Function to reverse a string
 * @param string
 * @param lenght
 *
 */
void reverse(char str[], int length)
{
    int start = 0;
    int end = length - 1;
    while (start < end) {
        char temp = str[start];
        str[start] = str[end];
        str[end] = temp;
        end--;
        start++;
    }
}

/**
 * @brief Implementation of itoa()
 * @param integer number
 * @param pointer to the string
 * @param numerical base
 * 
 */
char* itoa(int num, char* str, int base)
{
    int i = 0;
    bool isNegative = false;
 
    /* Handle 0 explicitly, otherwise empty string is
     * printed for 0 */
    if (num == 0) {
        str[i++] = '0';
        str[i] = '\0';
        return str;
    }
 
    // In standard itoa(), negative numbers are handled
    // only with base 10. Otherwise numbers are
    // considered unsigned.
    if (num < 0 && base == 10) {
        isNegative = true;
        num = -num;
    }
 
    // Process individual digits
    while (num != 0) {
        int rem = num % base;
        str[i++] = (rem > 9) ? (rem - 10) + 'a' : rem + '0';
        num = num / base;
    }
 
    // If number is negative, append '-'
    if (isNegative)
        str[i++] = '-';
 
    str[i] = '\0'; // Append string terminator
 
    // Reverse the string
    reverse(str, i);
 
    return str;
}

/**
 * @brief 
 *
 * 
 */
bool console_active(void) {
	return (chk_print_flag());
}


/*---------------------------------------------------*/
/* The purpose of this routine is to output data the */
/* same as the standard printf function without the  */
/* overhead most run-time libraries involve. Usually */
/* the printf brings in many kilobytes of code and   */
/* that is unacceptable in most embedded systems.    */
/*---------------------------------------------------*/
int nc_puts(const char *str)
{
	const u8_t *s = (const u8_t *) str;
	int n = 0;

	while (*s) {
//		if (*s == '\n')
//			n++;

		console_putc(*s);
		n++;
		s++;
	}
	return n;
}

/*---------------------------------------------------*/
/*                                                   */
/* This routine puts pad characters into the output  */
/* buffer.                                           */
/*                                                   */
static void padding( const s32 l_flag, const struct params_s *par)
{
    s32 i;

    if ((par->do_padding != 0) && (l_flag != 0) && (par->len < par->num1)) {
		i=(par->len);
        for (; i<(par->num1); i++) {
            console_putc( par->pad_character);
		}
    }
}

/*---------------------------------------------------*/
/*                                                   */
/* This routine moves a string to the output buffer  */
/* as directed by the padding and positioning flags. */
/*                                                   */
static void outs(const charptr lp, struct params_s *par)
{
    charptr LocalPtr;
	LocalPtr = lp;
    /* pad on left if needed                         */
	if(LocalPtr != NULL) {
		par->len = (s32)strlen( LocalPtr);
		padding( !(par->left_flag), par);
		/* Move string to the buffer                     */
		while (((*LocalPtr) != (char8)0) && ((par->num2) != 0)) {
			(par->num2)--;
			console_putc(*LocalPtr);
			LocalPtr += 1;
			//usleep(100);
//            k_sleep(K_MSEC(100));
		}
}

    /* Pad on right if needed                        */
    /* CR 439175 - elided next stmt. Seemed bogus.   */
    /* par->len = strlen( lp)                      */
    padding( par->left_flag, par);
}

/*---------------------------------------------------*/
/*                                                   */
/* This routine moves a number to the output buffer  */
/* as directed by the padding and positioning flags. */
/*                                                   */

static void outnum( const s32 n, const s32 base, struct params_s *par)
{
    s32 negative;
	s32 i;
    char8 outbuf[32];
    const char8 digits[] = "0123456789ABCDEF";
    u32 num;
    for(i = 0; i<32; i++) {
	outbuf[i] = '0';
    }

    /* Check if number is negative                   */
    if ((par->unsigned_flag == 0) && (base == 10) && (n < 0L)) {
        negative = 1;
		num =(-(n));
    }
    else{
        num = n;
        negative = 0;
    }

    /* Build number (backwards) in outbuf            */
    i = 0;
    do {
		outbuf[i] = digits[(num % base)];
		i++;
		num /= base;
    } while (num > 0);

    if (negative != 0) {
		outbuf[i] = '-';
		i++;
	}

    outbuf[i] = '\0';
    i--;

    /* Move the converted number to the buffer and   */
    /* add in the padding where needed.              */
    par->len = (s32)strlen(outbuf);
    padding( !(par->left_flag), par);
    while (&outbuf[i] >= outbuf) {
	console_putc( outbuf[i] );
		i--;
}
    padding( par->left_flag, par);
}

/*---------------------------------------------------*/
/*                                                   */
/* This routine gets a number from the format        */
/* string.                                           */
/*                                                   */
static s32 getnum(charptr* linep)
{
	s32 n = 0;
	s32 ResultIsDigit = 0;
	charptr cptr = *linep;

	while (cptr != NULL) {
		ResultIsDigit = isdigit(((s32)*cptr));
		if (ResultIsDigit == 0)
			break;
		n = ((n*10) + (((s32)*cptr) - (s32)'0'));
		cptr += 1;
	}

	*linep = ((charptr)(cptr));
	return(n);
}

/*---------------------------------------------------*/
/*                                                   */
/* This routine operates just like a printf/sprintf  */
/* routine. It outputs a set of data under the       */
/* control of a formatting string. Not all of the    */
/* standard C format control are supported. The ones */
/* provided are primarily those needed for embedded  */
/* systems work. Primarily the floating point        */
/* routines are omitted. Other formats could be      */
/* added easily by following the examples shown for  */
/* the supported formats.                            */
/*                                                   */
#ifdef DONGLE
/* void esp_printf( const func_ptr f_ptr,
   const charptr ctrl1, ...) */
void nc_printf( const char8 *ctrl1, ...)
{
	s32 Check;
    s32 dot_flag;

    params_t par;

    char8 ch;
    va_list argp;
    char8 *ctrl = (char8 *)ctrl1;

    va_start( argp, ctrl1);

    while ((ctrl != NULL) && (*ctrl != (char8)0)) {

        /* move format string chars to buffer until a  */
        /* format control is found.                    */
        if (*ctrl != '%') {
            console_putc(*ctrl);
			ctrl += 1;
            continue;
        }

        /* initialize all the flags for this format.   */
        dot_flag = 0;
        par.unsigned_flag = 0;
		par.left_flag = 0;
		par.do_padding = 0;
        par.pad_character = ' ';
        par.num2=32767;
		par.num1=0;
		par.len=0;

 try_next:
		if(ctrl != NULL) {
			ctrl += 1;
		}
		if(ctrl != NULL) {
			ch = *ctrl;
		} else {
			break;
		}

        if (isdigit((s32)ch) != 0) {
            if (dot_flag != 0) {
                par.num2 = getnum(&ctrl);
			}
            else {
                if (ch == '0') {
                    par.pad_character = '0';
				}
				if(ctrl != NULL) {
			par.num1 = getnum(&ctrl);
				}
                par.do_padding = 1;
            }
            if(ctrl != NULL) {
			ctrl -= 1;
			}
            goto try_next;
        }

        switch (tolower((s32)ch)) {
            case '%':
                console_putc( '%');
                Check = 1;
                break;

            case '-':
                par.left_flag = 1;
                Check = 0;
                break;

            case '.':
                dot_flag = 1;
                Check = 0;
                break;

            case 'l':
                Check = 0;
                break;

            case 'u':
                par.unsigned_flag = 1;
                /* fall through */
            case 'i':
            case 'd':
                outnum( va_arg(argp, s32), 10L, &par);
				Check = 1;
                break;
            case 'p':
                break;
            case 'X':
            case 'x':
                par.unsigned_flag = 1;
                outnum((s32)va_arg(argp, s32), 16L, &par);
                Check = 1;
                break;

            case 's':
                outs( va_arg( argp, char *), &par);
                Check = 1;
                break;

            case 'c':
                console_putc( va_arg( argp, s32));
                Check = 1;
                break;

            case '\\':
                switch (*ctrl) {
                    case 'a':
                        console_putc( ((char8)0x07));
                        break;
                    case 'h':
                        console_putc( ((char8)0x08));
                        break;
                    case 'r':
                        console_putc( ((char8)0x0D));
                        break;
                    case 'n':
                        console_putc( ((char8)0x0D));
                        console_putc( ((char8)0x0A));
                        break;
                    default:
                        console_putc( *ctrl);

                        break;
                }
                ctrl += 1;
                Check = 0;
                break;

            default:
		Check = 1;
		break;
        }
        if(Check == 1) {
			if(ctrl != NULL) {
				ctrl += 1;
			}
                continue;
        }
        goto try_next;
    }
    va_end( argp);
}
#endif

void ctrlc_handled(void)
{
	ctrlc_abort = 0;
}

/* test if ctrl-c was pressed */
int ctrlc(void)
{
	int ret = 0;

	if (ctrlc_abort)
		return 1;

//	if (nc_tstc() && nc_getchar() == 3)
//		ret = 1;

	if (ret)
		ctrlc_abort = 1;

	return ret;
}
```

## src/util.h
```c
/*
 * Copyright (c) 2025 Br1Ge9se
 * All rights reserved. 
 * 
 * Redistribution and use in source and binary forms, with or without modification, 
 * are permitted provided that the following conditions are met:
 *
 * 1. Redistributions of source code must retain the above copyright notice,
 *    this list of conditions and the following disclaimer.
 * 2. Redistributions in binary form must reproduce the above copyright notice,
 *    this list of conditions and the following disclaimer in the documentation
 *    and/or other materials provided with the distribution.
 * 3. The name of the author may not be used to endorse or promote products
 *    derived from this software without specific prior written permission. 
 *
 * THIS SOFTWARE IS PROVIDED BY THE AUTHOR ``AS IS'' AND ANY EXPRESS OR IMPLIED 
 * WARRANTIES, INCLUDING, BUT NOT LIMITED TO, THE IMPLIED WARRANTIES OF 
 * MERCHANTABILITY AND FITNESS FOR A PARTICULAR PURPOSE ARE DISCLAIMED. IN NO EVENT 
 * SHALL THE AUTHOR BE LIABLE FOR ANY DIRECT, INDIRECT, INCIDENTAL, SPECIAL, 
 * EXEMPLARY, OR CONSEQUENTIAL DAMAGES (INCLUDING, BUT NOT LIMITED TO, PROCUREMENT 
 * OF SUBSTITUTE GOODS OR SERVICES; LOSS OF USE, DATA, OR PROFITS; OR BUSINESS 
 * INTERRUPTION) HOWEVER CAUSED AND ON ANY THEORY OF LIABILITY, WHETHER IN 
 * CONTRACT, STRICT LIABILITY, OR TORT (INCLUDING NEGLIGENCE OR OTHERWISE) ARISING 
 * IN ANY WAY OUT OF THE USE OF THIS SOFTWARE, EVEN IF ADVISED OF THE POSSIBILITY 
 * OF SUCH DAMAGE.
 *
 * 
 * Author: Bruno Genovese <br1ge9se>
 *
 */
#ifndef __SHELL_UTIL_H__
#define __SHELL_UTIL_H__

#include <zephyr/kernel.h>
#include <stdarg.h>
#include <stdio.h>
#include <ctype.h>
#include <string.h>
#include <stdlib.h>
#include <sys/types.h>
#include <zephyr/drivers/uart.h>
#include "types.h"
#include "board_conf.h"
 
#define CFG_PBSIZE 256

#define VARSIZE	32
typedef struct {
	char name[VARSIZE];
	char value[VARSIZE];
} ENV;
#define ENVNUM	16

#define ERR_ENVFULL     1
#define ERR_ENVPARAM    2

typedef char8* charptr;
typedef s32 (*func_ptr)(int c);


typedef struct params_s {
    s32 len;
    s32 num1;
    s32 num2;
    char8 pad_character;
    s32 do_padding;
    s32 left_flag;
    s32 unsigned_flag;
} params_t;

/*               Prototypes                          */

void set_print_flag(bool val);

bool chk_print_flag(void);

#ifdef DONGLE
void nc_printf( const char8 *ctrl1, ...);
#else
#define nc_printf zprintf
#endif
#define my_printf nc_printf

//#define nc_printf zprintf

void ctrlc_handled(void);

int ctrlc(void);

int nc_puts(const char *str);

int setenv(const char * env_name, const char * env_value);

const char * getenv(const char *env_name);

void clrenv(void);

void initenv(void);

void init_console(const struct device *mydev);

void console_putc(unsigned char c);

static int console_puts(const char *str);

int zprintf(const char *fmt, ...);

void reverse(char str[], int length);

char* itoa(int num, char* str, int base);

bool console_active(void);

int nc_getchar(void);
 
#endif /* __SHELL_UTIL_H__ */
```
